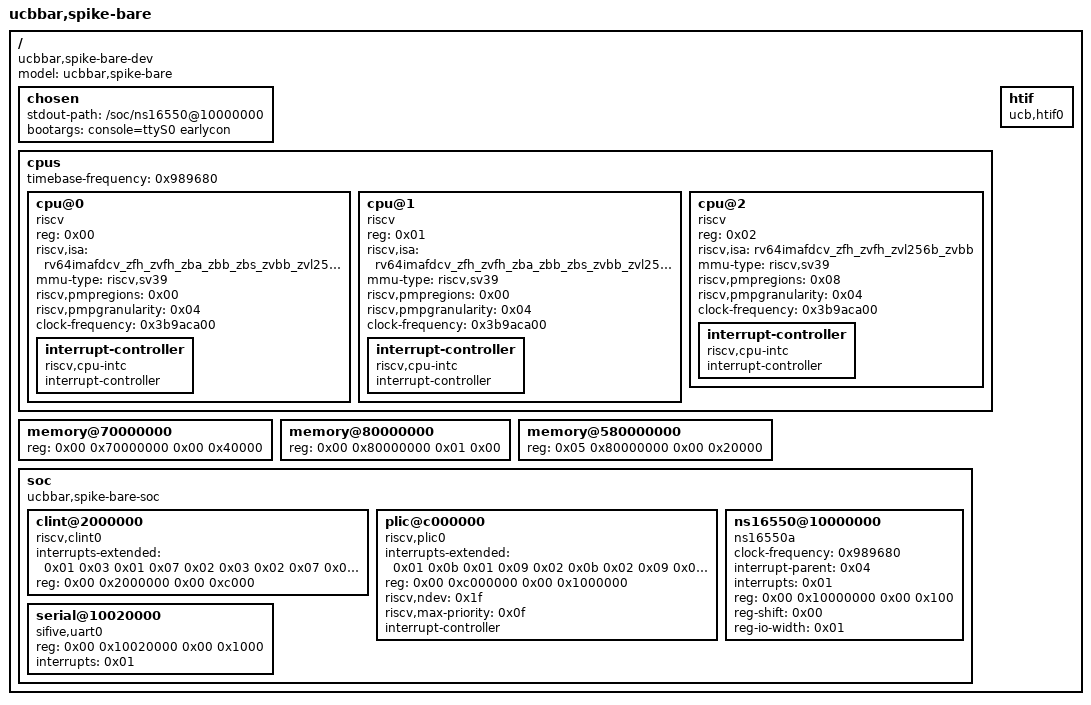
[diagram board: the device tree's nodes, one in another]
/dts-v1/;

/ {
	#address-cells = <0x02>;
	#size-cells = <0x02>;
	compatible = "ucbbar,spike-bare-dev";
	model = "ucbbar,spike-bare";

	chosen {
		stdout-path = "/soc/ns16550@10000000";
		bootargs = "console=ttyS0 earlycon";
	};

	cpus {
		#address-cells = <0x01>;
		#size-cells = <0x00>;
		timebase-frequency = <0x989680>;

		cpu@0 {
			device_type = "cpu";
			reg = <0x00>;
			status = "okay";
			compatible = "riscv";
			riscv,isa = "rv64imafdcv_zfh_zvfh_zba_zbb_zbs_zvbb_zvl256b_zvfofp8min_zvfbfmin_zvfbfa_zvt32t_zvti8i32mm_zvtofp8fmm";
			mmu-type = "riscv,sv39";
			riscv,pmpregions = <0x00>;
			riscv,pmpgranularity = <0x04>;
			clock-frequency = <0x3b9aca00>;

			interrupt-controller {
				#address-cells = <0x02>;
				#interrupt-cells = <0x01>;
				interrupt-controller;
				compatible = "riscv,cpu-intc";
				phandle = <0x01>;
			};
		};

		cpu@1 {
			device_type = "cpu";
			reg = <0x01>;
			status = "okay";
			compatible = "riscv";
			riscv,isa = "rv64imafdcv_zfh_zvfh_zba_zbb_zbs_zvbb_zvl256b_zvfofp8min_zvfbfmin_zvfbfa_zvt32t_zvti8i32mm_zvtofp8fmm";
			mmu-type = "riscv,sv39";
			riscv,pmpregions = <0x00>;
			riscv,pmpgranularity = <0x04>;
			clock-frequency = <0x3b9aca00>;

			interrupt-controller {
				#address-cells = <0x02>;
				#interrupt-cells = <0x01>;
				interrupt-controller;
				compatible = "riscv,cpu-intc";
				phandle = <0x02>;
			};
		};

		cpu@2 {
			device_type = "cpu";
			reg = <0x02>;
			status = "okay";
			compatible = "riscv";
			riscv,isa = "rv64imafdcv_zfh_zvfh_zvl256b_zvbb";
			mmu-type = "riscv,sv39";
			riscv,pmpregions = <0x08>;
			riscv,pmpgranularity = <0x04>;
			clock-frequency = <0x3b9aca00>;

			interrupt-controller {
				#address-cells = <0x02>;
				#interrupt-cells = <0x01>;
				interrupt-controller;
				compatible = "riscv,cpu-intc";
				phandle = <0x03>;
			};
		};
	};

	memory@70000000 {
		device_type = "memory";
		reg = <0x00 0x70000000 0x00 0x40000>;
	};

	memory@80000000 {
		device_type = "memory";
		reg = <0x00 0x80000000 0x01 0x00>;
	};

	memory@580000000 {
		device_type = "memory";
		reg = <0x05 0x80000000 0x00 0x20000>;
	};

	soc {
		#address-cells = <0x02>;
		#size-cells = <0x02>;
		compatible = "ucbbar,spike-bare-soc", "simple-bus";
		ranges;

		clint@2000000 {
			compatible = "riscv,clint0";
			interrupts-extended = <0x01 0x03 0x01 0x07 0x02 0x03 0x02 0x07 0x03 0x03 0x03 0x07>;
			reg = <0x00 0x2000000 0x00 0xc000>;
		};

		plic@c000000 {
			compatible = "riscv,plic0";
			#address-cells = <0x02>;
			interrupts-extended = <0x01 0x0b 0x01 0x09 0x02 0x0b 0x02 0x09 0x03 0x0b 0x03 0x09>;
			reg = <0x00 0xc000000 0x00 0x1000000>;
			riscv,ndev = <0x1f>;
			riscv,max-priority = <0x0f>;
			#interrupt-cells = <0x01>;
			interrupt-controller;
			phandle = <0x04>;
		};

		ns16550@10000000 {
			compatible = "ns16550a";
			clock-frequency = <0x989680>;
			interrupt-parent = <0x04>;
			interrupts = <0x01>;
			reg = <0x00 0x10000000 0x00 0x100>;
			reg-shift = <0x00>;
			reg-io-width = <0x01>;
		};

		serial@10020000 {
			compatible = "sifive,uart0";
			reg = <0x00 0x10020000 0x00 0x1000>;
			interrupts = <0x01>;
		};
	};

	htif {
		compatible = "ucb,htif0";
	};
};
